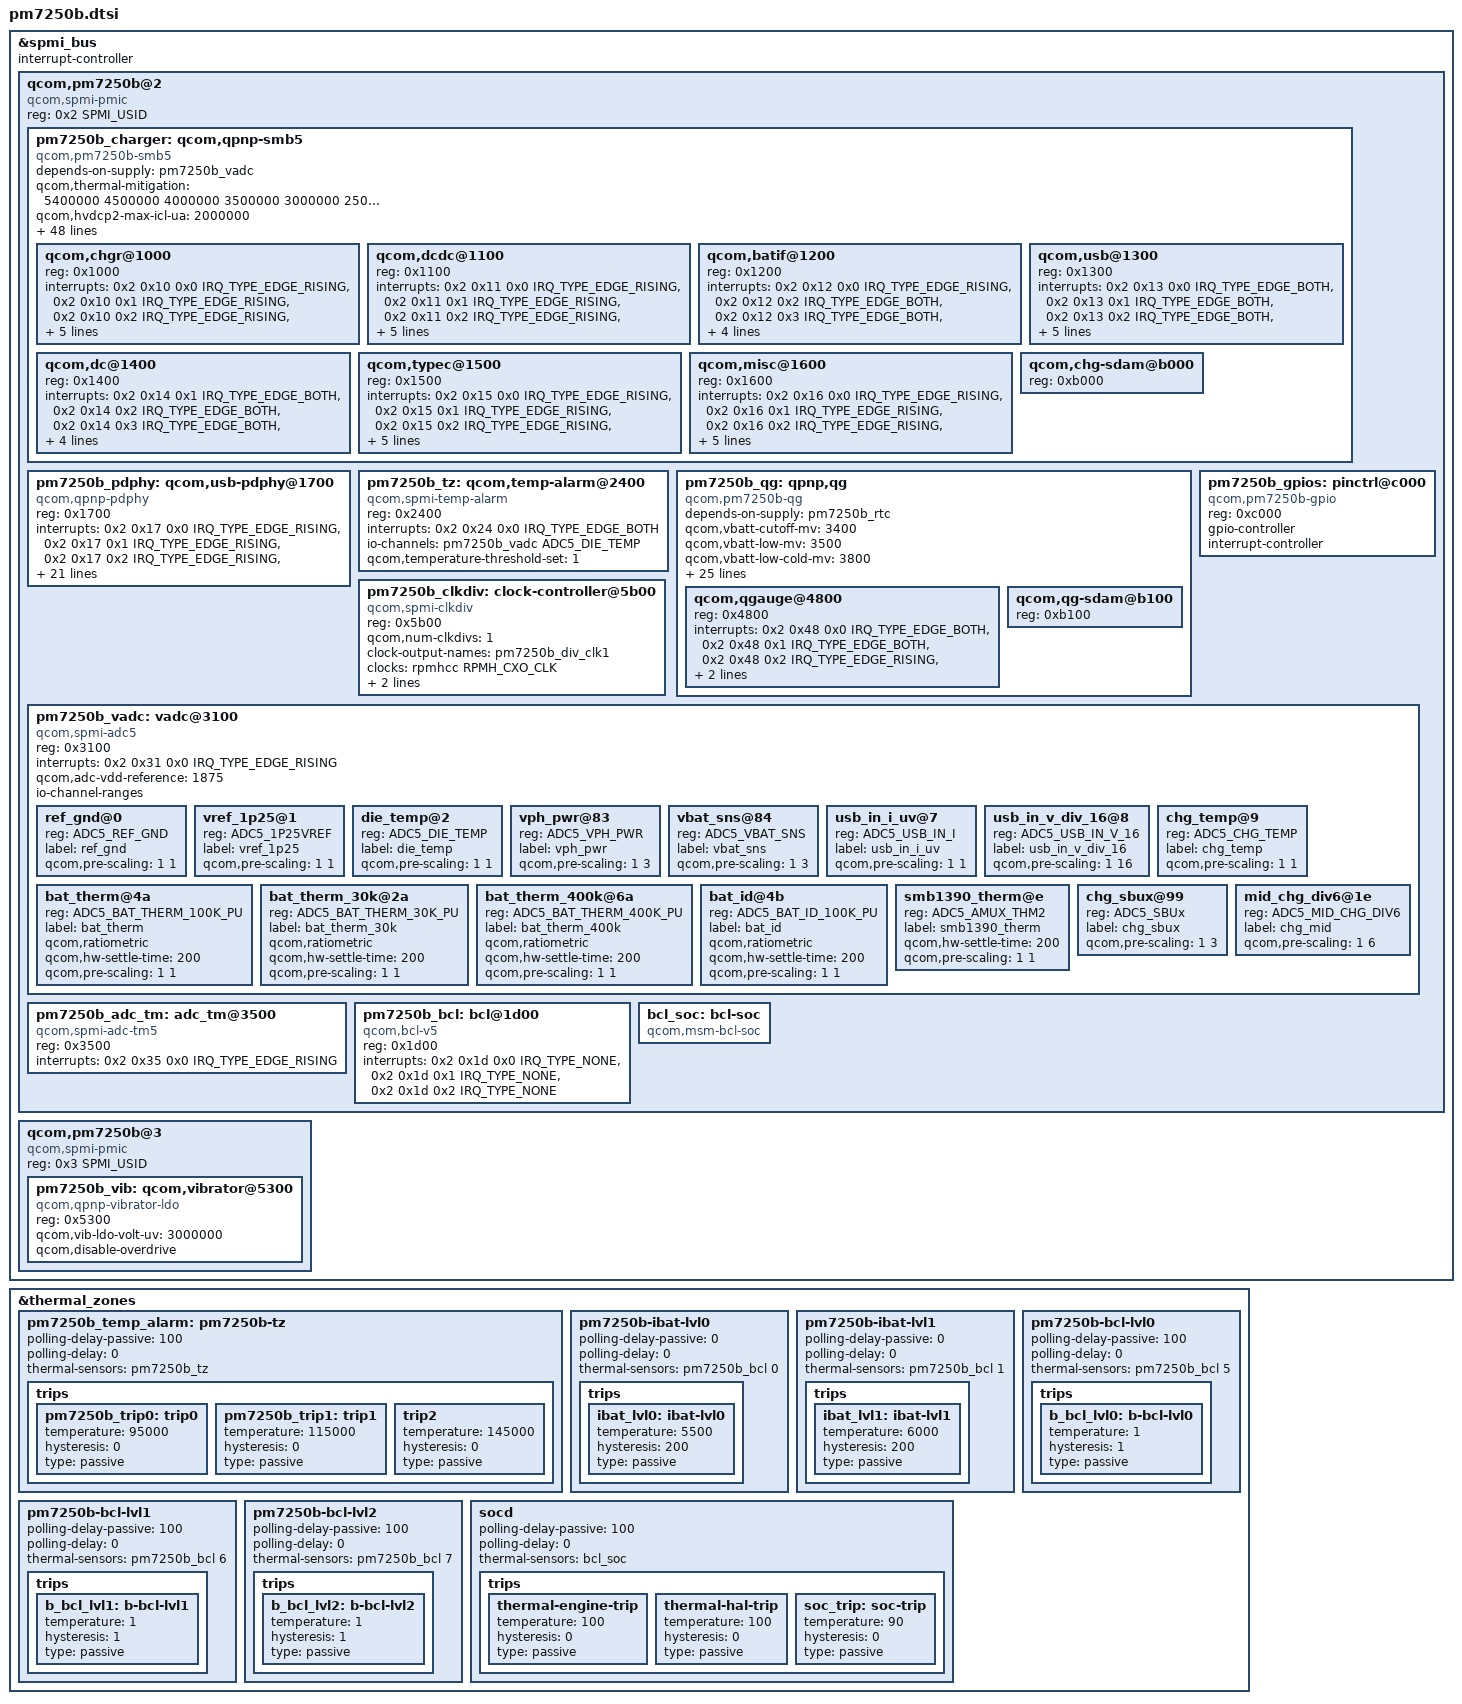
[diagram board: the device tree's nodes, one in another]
#include <dt-bindings/spmi/spmi.h>
#include <dt-bindings/interrupt-controller/irq.h>
#include <dt-bindings/iio/qcom,spmi-vadc.h>

&spmi_bus {
	#address-cells = <2>;
	#size-cells = <0>;
	interrupt-controller;
	#interrupt-cells = <4>;

	qcom,pm7250b@2 {
		compatible = "qcom,spmi-pmic";
		reg = <0x2 SPMI_USID>;
		#address-cells = <1>;
		#size-cells = <0>;

		pm7250b_charger: qcom,qpnp-smb5 {
			compatible = "qcom,pm7250b-smb5";
			depends-on-supply = <&pm7250b_vadc>;
			#address-cells = <1>;
			#size-cells = <1>;
			#cooling-cells = <2>;
			#io-channel-cells = <1>;

			qcom,thermal-mitigation = <5400000 4500000 4000000
				3500000 3000000 2500000 2000000 1500000
				1000000 500000 800000 800000
				800000 800000 800000 800000
				800000 800000>;
			qcom,hvdcp2-max-icl-ua = <2000000>;
			qcom,hvdcp2-12v-max-icl-ua = <1500000>;

			status = "okay";
			qcom,battery-data = <&mtp_batterydata>;
			qcom,sec-charger-config = <0>;
			qcom,auto-recharge-soc = <95>;
			qcom,auto-recharge-vbat-mv = <100>;
			qcom,step-charging-enable;
			qcom,sw-jeita-enable;
			qcom,distinguish-qc-class-ab;
			qcom,charger-temp-max = <800>;
			qcom,smb-temp-max = <800>;
			qcom,suspend-input-on-debug-batt;
			qcom,fcc-stepping-enable;
			qcom,fcc-step-delay-ms = <100>;
			qcom,fcc-step-size-ua = <100000>;
			qcom,smb-internal-pull-kohm = <0>;
			qcom,en-skin-therm-mitigation;
			qcom,hvdcp3-standalone-config;
			qcom,chg-term-current-ma = <(-250)>;
			qcom,fcc-max-ua = <6000000>;
			qcom,fv-max-uv = <4500000>;
			qcom,disable-suspend-on-collapse;
			dpdm-supply = <&usb2_phy0>;

			mi,use_third_cp;
			mi,support-ffc;

			io-channels =
				<&pm7250b_vadc ADC5_USB_IN_V_16>,
				<&pm7250b_vadc ADC5_USB_IN_I>,
				<&pm7250b_vadc ADC5_CHG_TEMP>,
				<&pm7250b_vadc ADC5_DIE_TEMP>,
				<&pm7250b_vadc ADC5_AMUX_THM1_100K_PU>,
				<&pm7250b_vadc ADC5_SBUx>,
				<&pm7250b_vadc ADC5_VPH_PWR>,
				<&pm7250b_vadc ADC5_AMUX_THM1_100K_PU>,
				<&pm7250b_qg   0x4b>,
				<&pm7250b_qg   0xa2>,
				<&pm7250b_qg   0x46>,
				<&pm7250b_qg   0x45>,
				<&pm7250b_qg   0x42>,
				<&pm7250b_qg   0x47>,
				<&pm7250b_qg   0x5d>,
				<&pm7250b_qg   0x4e>,
				<&pm7250b_qg   0x44>,
				<&pm7250b_qg   0x5b>,
				<&pm7250b_qg   0x48>,
				<&pm7250b_qg   0x2d>,
				<&pm7250b_qg   0x53>,
				<&pm7250b_qg   0x49>,
				<&pm7250b_qg   0x52>,
				<&pm7250b_qg   0x54>,
				<&pm7250b_qg   0x56>,
				<&pm7250b_qg   0xc1>,
				<&sc8541       0x98>,
				<&sc8541       0x9d>,
				<&auth_battery 0xb5>,
				<&auth_battery 0xb4>,
				<&auth_battery 0xb9>,
				<&auth_battery 0xbb>,
				<&bq25960      0x98>,
				<&bq25960      0x9d>,
				<&pm7250b_qg   0xa0>,
				<&pm7250b_qg   0xa1>,
				<&pm7250b_qg   0x9f>,
				<&pm7250b_qg   0x50>,
				<&bq25960      0xc4>,
				<&pm7250b_charger 0xc5>;

			io-channel-names =
				"usb_in_voltage", "usb_in_current", "chg_temp",
				"die_temp", "conn_temp", "sbux_res", "vph_voltage",
				"skin_temp", "resistance_id", "fastcharge_mode",
				"voltage_now", "temp", "capacity", "voltage_ocv",
				"voltage_avg", "debug_battery", "real_capacity",
				"cc_soc", "current_now", "voltage_max",
				"charge_full", "charge_counter", "cycle_count",
				"charge_full_design", "time_to_full_now",
				"ffc_chg_termination_current", "sc_bus_current",
				"sc_manufacturer", "auth_batt_id",
				"auth_authen_result", "auth_manufacturer",
				"auth_chip_ok", "bq_bus_current", "bq_manufacturer",
				"soc_decimal", "soc_decimal_rate", "shutdown_delay",
				"batt_full_current", "bq_set_acdrv", "recharg_mode";

			qcom,chgr@1000 {
				reg = <0x1000>;
				interrupts =
					<0x2 0x10 0x0 IRQ_TYPE_EDGE_RISING>,
					<0x2 0x10 0x1 IRQ_TYPE_EDGE_RISING>,
					<0x2 0x10 0x2 IRQ_TYPE_EDGE_RISING>,
					<0x2 0x10 0x3 IRQ_TYPE_EDGE_RISING>,
					<0x2 0x10 0x4 IRQ_TYPE_EDGE_RISING>,
					<0x2 0x10 0x5 IRQ_TYPE_EDGE_RISING>,
					<0x2 0x10 0x6 IRQ_TYPE_EDGE_RISING>,
					<0x2 0x10 0x7 IRQ_TYPE_EDGE_RISING>;
				interrupt-names = "chgr-error",
						  "chg-state-change",
						  "step-chg-state-change",
						  "step-chg-soc-update-fail",
						  "step-chg-soc-update-req",
						  "fg-fvcal-qualified",
						  "vph-alarm",
						  "vph-drop-prechg";
			};

			qcom,dcdc@1100 {
				reg = <0x1100>;
				interrupts =
					<0x2 0x11 0x0 IRQ_TYPE_EDGE_RISING>,
					<0x2 0x11 0x1 IRQ_TYPE_EDGE_RISING>,
					<0x2 0x11 0x2 IRQ_TYPE_EDGE_RISING>,
					<0x2 0x11 0x3 IRQ_TYPE_EDGE_BOTH>,
					<0x2 0x11 0x4 IRQ_TYPE_EDGE_BOTH>,
					<0x2 0x11 0x5 IRQ_TYPE_EDGE_BOTH>,
					<0x2 0x11 0x6 IRQ_TYPE_EDGE_RISING>,
					<0x2 0x11 0x7 IRQ_TYPE_EDGE_BOTH>;
				interrupt-names = "otg-fail",
						  "otg-oc-disable-sw",
						  "otg-oc-hiccup",
						  "bsm-active",
						  "high-duty-cycle",
						  "input-current-limiting",
						  "concurrent-mode-disable",
						  "switcher-power-ok";
			};

			qcom,batif@1200 {
				reg = <0x1200>;
				interrupts =
					<0x2 0x12 0x0 IRQ_TYPE_EDGE_RISING>,
					<0x2 0x12 0x2 IRQ_TYPE_EDGE_BOTH>,
					<0x2 0x12 0x3 IRQ_TYPE_EDGE_BOTH>,
					<0x2 0x12 0x4 IRQ_TYPE_EDGE_BOTH>,
					<0x2 0x12 0x5 IRQ_TYPE_EDGE_BOTH>,
					<0x2 0x12 0x6 IRQ_TYPE_EDGE_BOTH>,
					<0x2 0x12 0x7 IRQ_TYPE_EDGE_BOTH>;
				interrupt-names = "bat-temp",
						  "bat-ov",
						  "bat-low",
						  "bat-therm-or-id-missing",
						  "bat-terminal-missing",
						  "buck-oc",
						  "vph-ov";
			};

			qcom,usb@1300 {
				reg = <0x1300>;
				interrupts =
					<0x2 0x13 0x0 IRQ_TYPE_EDGE_BOTH>,
					<0x2 0x13 0x1 IRQ_TYPE_EDGE_BOTH>,
					<0x2 0x13 0x2 IRQ_TYPE_EDGE_BOTH>,
					<0x2 0x13 0x3 IRQ_TYPE_EDGE_BOTH>,
					<0x2 0x13 0x4 IRQ_TYPE_EDGE_BOTH>,
					<0x2 0x13 0x5 IRQ_TYPE_EDGE_BOTH>,
					<0x2 0x13 0x6 IRQ_TYPE_EDGE_RISING>,
					<0x2 0x13 0x7 IRQ_TYPE_EDGE_RISING>;
				interrupt-names = "usbin-collapse",
						  "usbin-vashdn",
						  "usbin-uv",
						  "usbin-ov",
						  "usbin-plugin",
						  "usbin-revi-change",
						  "usbin-src-change",
						  "usbin-icl-change";
			};

			qcom,dc@1400 {
				reg = <0x1400>;
				interrupts =
					<0x2 0x14 0x1 IRQ_TYPE_EDGE_BOTH>,
					<0x2 0x14 0x2 IRQ_TYPE_EDGE_BOTH>,
					<0x2 0x14 0x3 IRQ_TYPE_EDGE_BOTH>,
					<0x2 0x14 0x4 IRQ_TYPE_EDGE_BOTH>,
					<0x2 0x14 0x5 IRQ_TYPE_EDGE_BOTH>,
					<0x2 0x14 0x6 IRQ_TYPE_EDGE_RISING>,
					<0x2 0x14 0x7 IRQ_TYPE_EDGE_RISING>;
				interrupt-names = "dcin-vashdn",
						  "dcin-uv",
						  "dcin-ov",
						  "dcin-plugin",
						  "dcin-revi",
						  "dcin-pon",
						  "dcin-en";
			};

			qcom,typec@1500 {
				reg = <0x1500>;
				interrupts =
					<0x2 0x15 0x0 IRQ_TYPE_EDGE_RISING>,
					<0x2 0x15 0x1 IRQ_TYPE_EDGE_RISING>,
					<0x2 0x15 0x2 IRQ_TYPE_EDGE_RISING>,
					<0x2 0x15 0x3 IRQ_TYPE_EDGE_RISING>,
					<0x2 0x15 0x4 IRQ_TYPE_EDGE_RISING>,
					<0x2 0x15 0x5 IRQ_TYPE_EDGE_RISING>,
					<0x2 0x15 0x6 IRQ_TYPE_EDGE_RISING>,
					<0x2 0x15 0x7 IRQ_TYPE_EDGE_RISING>;
				interrupt-names = "typec-or-rid-detect-change",
						  "typec-vpd-detect",
						  "typec-cc-state-change",
						  "typec-vconn-oc",
						  "typec-vbus-change",
						  "typec-attach-detach",
						  "typec-legacy-cable-detect",
						  "typec-try-snk-src-detect";
			};

			qcom,misc@1600 {
				reg = <0x1600>;
				interrupts =
					<0x2 0x16 0x0 IRQ_TYPE_EDGE_RISING>,
					<0x2 0x16 0x1 IRQ_TYPE_EDGE_RISING>,
					<0x2 0x16 0x2 IRQ_TYPE_EDGE_RISING>,
					<0x2 0x16 0x3 IRQ_TYPE_EDGE_RISING>,
					<0x2 0x16 0x4 IRQ_TYPE_EDGE_BOTH>,
					<0x2 0x16 0x5 IRQ_TYPE_EDGE_RISING>,
					<0x2 0x16 0x6 IRQ_TYPE_EDGE_RISING>,
					<0x2 0x16 0x7 IRQ_TYPE_EDGE_RISING>;
				interrupt-names = "wdog-snarl",
						  "wdog-bark",
						  "aicl-fail",
						  "aicl-done",
						  "smb-en",
						  "imp-trigger",
						  "temp-change",
						  "temp-change-smb";
			};

			qcom,chg-sdam@b000 {
				reg = <0xb000>;
			};
		};

		pm7250b_pdphy: qcom,usb-pdphy@1700 {
			compatible = "qcom,qpnp-pdphy";
			reg = <0x1700>;
			interrupts = <0x2 0x17 0x0 IRQ_TYPE_EDGE_RISING>,
				     <0x2 0x17 0x1 IRQ_TYPE_EDGE_RISING>,
				     <0x2 0x17 0x2 IRQ_TYPE_EDGE_RISING>,
				     <0x2 0x17 0x3 IRQ_TYPE_EDGE_RISING>,
				     <0x2 0x17 0x4 IRQ_TYPE_EDGE_RISING>,
				     <0x2 0x17 0x5 IRQ_TYPE_EDGE_RISING>,
				     <0x2 0x17 0x6 IRQ_TYPE_EDGE_RISING>,
				     <0x2 0x17 0x7 IRQ_TYPE_EDGE_RISING>;

			interrupt-names = "sig-tx",
					  "sig-rx",
					  "msg-tx",
					  "msg-rx",
					  "msg-tx-failed",
					  "msg-tx-discarded",
					  "msg-rx-discarded",
					  "fr-swap";
			#io-channel-cells = <1>;

			qcom,default-sink-caps = <5000 3000>,
						 <9000 3000>,
						 <12000 2250>;

			vdd-pdphy-supply = <&pm6125_l15>;
			vbus-supply = <&pm7250b_smb5_vbus>;
			vconn-supply = <&pm7250b_smb5_vconn>;

			mi,pd_curr_limit = <1>;
			mi,limit_pd_unverified_pps_vbus = <1>;
			mi,pd_unverified_pps_max_vbus_limit = <9500000>;

			io-channels =
				<&pm7250b_charger 0x04>,
				<&pm7250b_charger 0x03>,
				<&pm7250b_charger 0x0d>,
				<&pm7250b_charger 0x02>,
				<&pm7250b_charger 0x1f>,
				<&pm7250b_charger 0x1d>,
				<&pm7250b_charger 0x1e>,
				<&pm7250b_charger 0x00>,
				<&pm7250b_charger 0x20>,
				<&pm7250b_charger 0x0c>,
				<&pm7250b_charger 0x0b>,
				<&pm7250b_charger 0x0a>,
				<&pm7250b_charger 0x01>,
				<&pm7250b_charger 0x07>;
			io-channel-names =
				"pd_active", "typec_cc_orientation",
				"connector_type", "typec_power_role",
				"pd_usb_suspend_supported", "typec_src_rp",
				"pd_in_hard_reset", "pr_current_max",
				"pr_swap", "pd_voltage_min",
				"pd_voltage_max", "real_type",
				"typec_mode", "pe_start";
		};

		pm7250b_tz: qcom,temp-alarm@2400 {
			compatible = "qcom,spmi-temp-alarm";
			reg = <0x2400>;
			interrupts = <0x2 0x24 0x0 IRQ_TYPE_EDGE_BOTH>;
			io-channels = <&pm7250b_vadc ADC5_DIE_TEMP>;
			io-channel-names = "thermal";
			#thermal-sensor-cells = <0>;
			qcom,temperature-threshold-set = <1>;
		};

		pm7250b_qg: qpnp,qg {
			compatible = "qcom,pm7250b-qg";
			#address-cells = <1>;
			#size-cells = <1>;
			#io-channel-cells = <1>;

			depends-on-supply = <&pm7250b_rtc>;

			qcom,vbatt-cutoff-mv = <3400>;
			qcom,vbatt-low-mv = <3500>;
			qcom,vbatt-low-cold-mv = <3800>;
			qcom,vbatt-empty-mv = <3000>;
			qcom,vbatt-empty-cold-mv = <3000>;
			qcom,s3-entry-fifo-length = <2>;

			status = "okay";
			qcom,battery-data = <&mtp_batterydata>;
			qcom,qg-iterm-ma = <300>;
			qcom,hold-soc-while-full;
			qcom,linearize-soc;
			qcom,cl-feedback-on;
			qcom,tcss-enable;
			qcom,fvss-enable;
			qcom,fvss-vbatt-mv = <3600>;
			qcom,bass-enable;
			qcom,s3-entry-ibat-ua = <25000>;
			qcom,s3-exit-ibat-ua = <45000>;
			qcom,qg-ext-sns;
			qcom,shutdown-delay-enable;

			qcom,soc_decimal_rate = <
				0  32
				10 30
				20 28
				30 28
				40 28
				50 28
				60 28
				70 28
				80 28
				90 26
				95 10
				99 5>;

			io-channels =
				<&pm7250b_vadc ADC5_BAT_THERM_30K_PU>,
				<&pm7250b_vadc ADC5_BAT_ID_100K_PU>,
				<&pm7250b_charger 0x37>,
				<&pm7250b_charger 0x3f>,
				<&pm7250b_charger 0x40>,
				<&pm7250b_charger 0x39>,
				<&sc8541       0x76>,
				<&sc8541       0x94>,
				<&bq25960      0x76>,
				<&bq25960      0x94>,
				<&pm7250b_charger 0x0a>;
			io-channel-names =
				"batt-therm", "batt-id",
				"input_current_limited", "recharge_soc",
				"force_recharge", "charge_done",
				"charging_enabled", "sc_battery_voltage",
				"bq_charging_enabled", "bq_battery_voltage",
				"real_type";

			qcom,qgauge@4800 {
				status = "okay";
				reg = <0x4800>;
				interrupts =
					<0x2 0x48 0x0 IRQ_TYPE_EDGE_BOTH>,
					<0x2 0x48 0x1 IRQ_TYPE_EDGE_BOTH>,
					<0x2 0x48 0x2 IRQ_TYPE_EDGE_RISING>,
					<0x2 0x48 0x3 IRQ_TYPE_EDGE_RISING>,
					<0x2 0x48 0x4 IRQ_TYPE_EDGE_RISING>;
				interrupt-names = "qg-batt-missing",
						  "qg-vbat-low",
						  "qg-vbat-empty",
						  "qg-fifo-done",
						  "qg-good-ocv";
			};

			qcom,qg-sdam@b100 {
				status = "okay";
				reg = <0xb100>;
			};
		};

		pm7250b_clkdiv: clock-controller@5b00 {
			compatible = "qcom,spmi-clkdiv";
			reg = <0x5b00>;
			#clock-cells = <1>;
			qcom,num-clkdivs = <1>;
			clock-output-names = "pm7250b_div_clk1";
			clocks = <&rpmhcc RPMH_CXO_CLK>;
			clock-names = "xo";
			assigned-clocks = <&pm7250b_clkdiv 1>;
			assigned-clock-rates = <19200000>;
		};

		pm7250b_gpios: pinctrl@c000 {
			compatible = "qcom,pm7250b-gpio";
			reg = <0xc000>;
			gpio-controller;
			#gpio-cells = <2>;
			interrupt-controller;
			#interrupt-cells = <2>;
		};

		pm7250b_vadc: vadc@3100 {
			compatible = "qcom,spmi-adc5";
			reg = <0x3100>;
			reg-names = "adc5-usr-base";
			#address-cells = <1>;
			#size-cells = <0>;
			interrupts = <0x2 0x31 0x0 IRQ_TYPE_EDGE_RISING>;
			interrupt-names = "eoc-int-en-set";
			qcom,adc-vdd-reference = <1875>;
			#io-channel-cells = <1>;
			io-channel-ranges;

			ref_gnd@0 {
				reg = <ADC5_REF_GND>;
				label = "ref_gnd";
				qcom,pre-scaling = <1 1>;
			};

			vref_1p25@1 {
				reg = <ADC5_1P25VREF>;
				label = "vref_1p25";
				qcom,pre-scaling = <1 1>;
			};

			die_temp@2 {
				reg = <ADC5_DIE_TEMP>;
				label = "die_temp";
				qcom,pre-scaling = <1 1>;
			};

			vph_pwr@83 {
				reg = <ADC5_VPH_PWR>;
				label = "vph_pwr";
				qcom,pre-scaling = <1 3>;
			};

			vbat_sns@84 {
				reg = <ADC5_VBAT_SNS>;
				label = "vbat_sns";
				qcom,pre-scaling = <1 3>;
			};

			usb_in_i_uv@7 {
				reg = <ADC5_USB_IN_I>;
				label = "usb_in_i_uv";
				qcom,pre-scaling = <1 1>;
			};

			usb_in_v_div_16@8 {
				reg = <ADC5_USB_IN_V_16>;
				label = "usb_in_v_div_16";
				qcom,pre-scaling = <1 16>;
			};

			chg_temp@9 {
				reg = <ADC5_CHG_TEMP>;
				label = "chg_temp";
				qcom,pre-scaling = <1 1>;
			};

			bat_therm@4a {
				reg = <ADC5_BAT_THERM_100K_PU>;
				label = "bat_therm";
				qcom,ratiometric;
				qcom,hw-settle-time = <200>;
				qcom,pre-scaling = <1 1>;
			};

			bat_therm_30k@2a {
				reg = <ADC5_BAT_THERM_30K_PU>;
				label = "bat_therm_30k";
				qcom,ratiometric;
				qcom,hw-settle-time = <200>;
				qcom,pre-scaling = <1 1>;
			};

			bat_therm_400k@6a {
				reg = <ADC5_BAT_THERM_400K_PU>;
				label = "bat_therm_400k";
				qcom,ratiometric;
				qcom,hw-settle-time = <200>;
				qcom,pre-scaling = <1 1>;
			};

			bat_id@4b {
				reg = <ADC5_BAT_ID_100K_PU>;
				label = "bat_id";
				qcom,ratiometric;
				qcom,hw-settle-time = <200>;
				qcom,pre-scaling = <1 1>;
			};

			smb1390_therm@e {
				reg = <ADC5_AMUX_THM2>;
				label = "smb1390_therm";
				qcom,hw-settle-time = <200>;
				qcom,pre-scaling = <1 1>;
			};

			chg_sbux@99 {
				reg = <ADC5_SBUx>;
				label = "chg_sbux";
				qcom,pre-scaling = <1 3>;
			};

			mid_chg_div6@1e {
				reg = <ADC5_MID_CHG_DIV6>;
				label = "chg_mid";
				qcom,pre-scaling = <1 6>;
			};
		};

		pm7250b_adc_tm: adc_tm@3500 {
			compatible = "qcom,spmi-adc-tm5";
			reg = <0x3500>;
			interrupts = <0x2 0x35 0x0 IRQ_TYPE_EDGE_RISING>;
			interrupt-names = "pm-adc-tm5";
			#address-cells = <1>;
			#size-cells = <0>;
			#thermal-sensor-cells = <1>;
			status = "okay";
		};

		pm7250b_bcl: bcl@1d00 {
			compatible = "qcom,bcl-v5";
			reg = <0x1d00>;
			interrupts = <0x2 0x1d 0x0 IRQ_TYPE_NONE>,
					<0x2 0x1d 0x1 IRQ_TYPE_NONE>,
					<0x2 0x1d 0x2 IRQ_TYPE_NONE>;
			interrupt-names = "bcl-lvl0",
						"bcl-lvl1",
						"bcl-lvl2";
			#thermal-sensor-cells = <1>;
		};

		bcl_soc:bcl-soc {
			compatible = "qcom,msm-bcl-soc";
			#thermal-sensor-cells = <0>;
		};
	};

	qcom,pm7250b@3 {
		compatible = "qcom,spmi-pmic";
		reg = <0x3 SPMI_USID>;
		#address-cells = <1>;
		#size-cells = <0>;

		pm7250b_vib: qcom,vibrator@5300 {
			compatible = "qcom,qpnp-vibrator-ldo";
			reg = <0x5300>;
			qcom,vib-ldo-volt-uv = <3000000>;
			qcom,disable-overdrive;
		};
	};
};

&thermal_zones {
	pm7250b_temp_alarm: pm7250b-tz {
		polling-delay-passive = <100>;
		polling-delay = <0>;
		thermal-sensors = <&pm7250b_tz>;

		trips {
			pm7250b_trip0: trip0 {
				temperature = <95000>;
				hysteresis = <0>;
				type = "passive";
			};

			pm7250b_trip1: trip1 {
				temperature = <115000>;
				hysteresis = <0>;
				type = "passive";
			};

			trip2 {
				temperature = <145000>;
				hysteresis = <0>;
				type = "passive";
			};
		};
	};

	pm7250b-ibat-lvl0 {
		polling-delay-passive = <0>;
		polling-delay = <0>;
		thermal-sensors = <&pm7250b_bcl 0>;

		trips {
			ibat_lvl0:ibat-lvl0 {
				temperature = <5500>;
				hysteresis = <200>;
				type = "passive";
			};
		};
	};

	pm7250b-ibat-lvl1 {
		polling-delay-passive = <0>;
		polling-delay = <0>;
		thermal-sensors = <&pm7250b_bcl 1>;

		trips {
			ibat_lvl1:ibat-lvl1 {
				temperature = <6000>;
				hysteresis = <200>;
				type = "passive";
			};
		};
	};

	pm7250b-bcl-lvl0 {
		polling-delay-passive = <100>;
		polling-delay = <0>;
		thermal-sensors = <&pm7250b_bcl 5>;

		trips {
			b_bcl_lvl0: b-bcl-lvl0 {
				temperature = <1>;
				hysteresis = <1>;
				type = "passive";
			};
		};
	};

	pm7250b-bcl-lvl1 {
		polling-delay-passive = <100>;
		polling-delay = <0>;
		thermal-sensors = <&pm7250b_bcl 6>;

		trips {
			b_bcl_lvl1: b-bcl-lvl1 {
				temperature = <1>;
				hysteresis = <1>;
				type = "passive";
			};
		};
	};

	pm7250b-bcl-lvl2 {
		polling-delay-passive = <100>;
		polling-delay = <0>;
		thermal-sensors = <&pm7250b_bcl 7>;

		trips {
			b_bcl_lvl2: b-bcl-lvl2 {
				temperature = <1>;
				hysteresis = <1>;
				type = "passive";
			};
        };
	};

	socd {
		polling-delay-passive = <100>;
		polling-delay = <0>;
		thermal-sensors = <&bcl_soc>;

		trips {
			thermal-engine-trip {
				temperature = <100>;
				hysteresis = <0>;
				type = "passive";
			};

			thermal-hal-trip {
				temperature = <100>;
				hysteresis = <0>;
				type = "passive";
			};

			soc_trip:soc-trip {
				temperature = <90>;
				hysteresis = <0>;
				type = "passive";
			};
		};
	};
};
